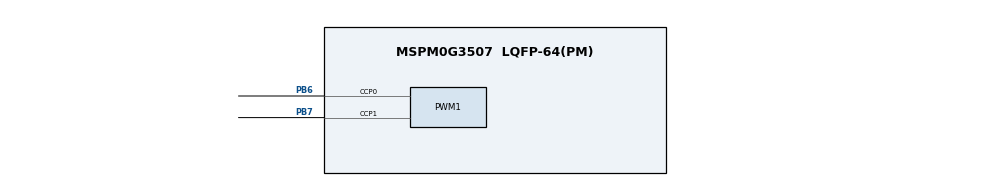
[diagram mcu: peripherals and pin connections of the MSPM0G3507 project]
/**
 * These arguments were used when this file was generated. They will be automatically applied on subsequent loads
 * via the GUI or CLI. Run CLI with '--help' for additional information on how to override these arguments.
 * @cliArgs --device "MSPM0G350X" --part "Default" --package "LQFP-64(PM)" --product "mspm0_sdk@2.05.01.01"
 * @v2CliArgs --device "MSPM0G3507" --package "LQFP-64(PM)" --product "mspm0_sdk@2.05.01.01"
 * @versions {"tool":"1.24.0+4110"}
 */

/**
 * Import the modules used in this configuration.
 */
const GPIO   = scripting.addModule("/ti/driverlib/GPIO", {}, false);
const GPIO1  = GPIO.addInstance();
const GPIO2  = GPIO.addInstance();
const GPIO3  = GPIO.addInstance();
const PWM    = scripting.addModule("/ti/driverlib/PWM", {}, false);
const PWM1   = PWM.addInstance();
const SYSCTL = scripting.addModule("/ti/driverlib/SYSCTL");

/**
 * Write custom configuration values to the imported modules.
 */
GPIO1.$name                         = "Direction";
GPIO1.port                          = "PORTB";
GPIO1.associatedPins.create(4);
GPIO1.associatedPins[0].$name       = "AIN1";
GPIO1.associatedPins[0].assignedPin = "2";
GPIO1.associatedPins[1].$name       = "AIN2";
GPIO1.associatedPins[1].assignedPin = "3";
GPIO1.associatedPins[2].$name       = "BIN1";
GPIO1.associatedPins[2].assignedPin = "12";
GPIO1.associatedPins[3].$name       = "BIN2";
GPIO1.associatedPins[3].assignedPin = "13";

const Board = scripting.addModule("/ti/driverlib/Board", {}, false);

GPIO2.$name                         = "INPUTA";
GPIO2.port                          = "PORTA";
GPIO2.portSegment                   = "Upper";
GPIO2.associatedPins.create(3);
GPIO2.associatedPins[0].direction   = "INPUT";
GPIO2.associatedPins[0].assignedPin = "27";
GPIO2.associatedPins[0].$name       = "IN1";
GPIO2.associatedPins[1].$name       = "IN2";
GPIO2.associatedPins[1].direction   = "INPUT";
GPIO2.associatedPins[1].assignedPin = "25";
GPIO2.associatedPins[2].$name       = "IN5";
GPIO2.associatedPins[2].direction   = "INPUT";
GPIO2.associatedPins[2].assignedPin = "16";

GPIO3.$name                         = "INPUTB";
GPIO3.port                          = "PORTB";
GPIO3.portSegment                   = "Upper";
GPIO3.associatedPins.create(5);
GPIO3.associatedPins[0].direction   = "INPUT";
GPIO3.associatedPins[0].assignedPin = "25";
GPIO3.associatedPins[0].$name       = "IN3";
GPIO3.associatedPins[1].$name       = "IN4";
GPIO3.associatedPins[1].assignedPin = "20";
GPIO3.associatedPins[1].direction   = "INPUT";
GPIO3.associatedPins[2].$name       = "IN6";
GPIO3.associatedPins[2].direction   = "INPUT";
GPIO3.associatedPins[2].assignedPin = "17";
GPIO3.associatedPins[3].$name       = "IN8";
GPIO3.associatedPins[3].direction   = "INPUT";
GPIO3.associatedPins[3].assignedPin = "21";
GPIO3.associatedPins[4].$name       = "IN7";
GPIO3.associatedPins[4].direction   = "INPUT";
GPIO3.associatedPins[4].assignedPin = "19";

PWM1.$name                              = "PWM_MOTOR";
PWM1.clockDivider                       = 8;
PWM1.timerStartTimer                    = true;
PWM1.pwmMode                            = "EDGE_ALIGN_UP";
PWM1.peripheral.ccp0Pin.$assign         = "PB6";
PWM1.peripheral.ccp1Pin.$assign         = "PB7";
PWM1.PWM_CHANNEL_0.$name                = "ti_driverlib_pwm_PWMTimerCC0";
PWM1.PWM_CHANNEL_1.$name                = "ti_driverlib_pwm_PWMTimerCC1";
PWM1.ccp0PinConfig.$name                = "ti_driverlib_gpio_GPIOPinGeneric0";
PWM1.ccp0PinConfig.direction            = scripting.forceWrite("OUTPUT");
PWM1.ccp0PinConfig.hideOutputInversion  = scripting.forceWrite(false);
PWM1.ccp0PinConfig.onlyInternalResistor = scripting.forceWrite(false);
PWM1.ccp0PinConfig.passedPeripheralType = scripting.forceWrite("Digital");
PWM1.ccp1PinConfig.$name                = "ti_driverlib_gpio_GPIOPinGeneric1";
PWM1.ccp1PinConfig.direction            = scripting.forceWrite("OUTPUT");
PWM1.ccp1PinConfig.hideOutputInversion  = scripting.forceWrite(false);
PWM1.ccp1PinConfig.onlyInternalResistor = scripting.forceWrite(false);
PWM1.ccp1PinConfig.passedPeripheralType = scripting.forceWrite("Digital");

SYSCTL.forceDefaultClkConfig = true;

/**
 * Pinmux solution for unlocked pins/peripherals. This ensures that minor changes to the automatic solver in a future
 * version of the tool will not impact the pinmux you originally saw.  These lines can be completely deleted in order to
 * re-solve from scratch.
 */
GPIO1.associatedPins[0].pin.$suggestSolution = "PB2";
GPIO1.associatedPins[1].pin.$suggestSolution = "PB3";
GPIO1.associatedPins[2].pin.$suggestSolution = "PB12";
GPIO1.associatedPins[3].pin.$suggestSolution = "PB13";
Board.peripheral.$suggestSolution            = "DEBUGSS";
Board.peripheral.swclkPin.$suggestSolution   = "PA20";
Board.peripheral.swdioPin.$suggestSolution   = "PA19";
GPIO2.associatedPins[0].pin.$suggestSolution = "PA27";
GPIO2.associatedPins[1].pin.$suggestSolution = "PA25";
GPIO2.associatedPins[2].pin.$suggestSolution = "PA16";
GPIO3.associatedPins[0].pin.$suggestSolution = "PB25";
GPIO3.associatedPins[1].pin.$suggestSolution = "PB20";
GPIO3.associatedPins[2].pin.$suggestSolution = "PB17";
GPIO3.associatedPins[3].pin.$suggestSolution = "PB21";
GPIO3.associatedPins[4].pin.$suggestSolution = "PB19";
PWM1.peripheral.$suggestSolution             = "TIMG6";
SYSCTL.peripheral.$suggestSolution           = "SYSCTL";
